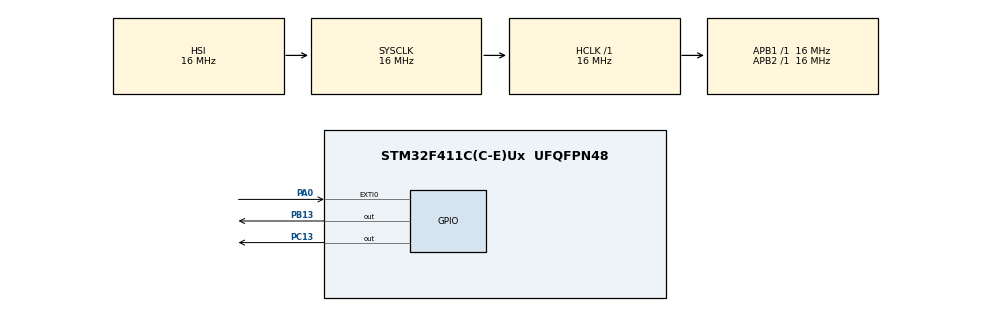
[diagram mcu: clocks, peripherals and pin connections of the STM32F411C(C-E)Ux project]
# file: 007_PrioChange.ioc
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Mcu.Family=STM32F4
Mcu.Name=STM32F411C(C-E)Ux
Mcu.Package=UFQFPN48
NVIC.EXTI0_IRQn=true\:6\:0\:true\:false\:true\:true\:true\:true
NVIC.PriorityGroup=NVIC_PRIORITYGROUP_4
NVIC.TIM2_IRQn=true\:15\:0\:false\:false\:true\:false\:true\:true
NVIC.TimeBase=TIM2_IRQn
NVIC.TimeBaseIP=TIM2
PA0-WKUP.GPIO_ModeDefaultEXTI=GPIO_MODE_IT_FALLING
PA0-WKUP.GPIO_PuPd=GPIO_PULLUP
PA0-WKUP.Signal=GPXTI0
PB13.Signal=GPIO_Output
PC13-ANTI_TAMP.Signal=GPIO_Output
ProjectManager.HeapSize=0x200
ProjectManager.StackSize=0x400
ProjectManager.TargetToolchain=STM32CubeIDE
RCC.AHBFreq_Value=16000000
RCC.APB1Freq_Value=16000000
RCC.APB2Freq_Value=16000000
RCC.CortexFreq_Value=16000000
RCC.HSE_VALUE=25000000
RCC.HSI_VALUE=16000000
RCC.LSE_VALUE=32768
RCC.SYSCLKFreq_VALUE=16000000
RCC.VCOOutputFreq_Value=192000000
VP_SYS_VS_tim2.Mode=TIM2
board=custom

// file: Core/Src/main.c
/* USER CODE BEGIN Header */
/**
  ******************************************************************************
  * @file           : main.c
  * @brief          : Main program body
  ******************************************************************************
  * @attention
  *
  * Copyright (c) 2025 STMicroelectronics.
  * All rights reserved.
  *
  * This software is licensed under terms that can be found in the LICENSE file
  * in the root directory of this software component.
  * If no LICENSE file comes with this software, it is provided AS-IS.
  *
  ******************************************************************************
  */
/* USER CODE END Header */
#include "main.h"

/* USER CODE BEGIN Includes */
#include <stdio.h>
#include "FreeRTOS.h"
#include "task.h"

/* USER CODE END Includes */

/* USER CODE BEGIN PV */
#define DWT_CTRL   ( *(volatile uint32_t*) 0xE0001000 )
/* USER CODE END PV */

void SystemClock_Config(void);
static void MX_GPIO_Init(void);
/* USER CODE BEGIN PFP */
static void led1_handler(void* parameters);
static void led2_handler(void* parameters);
TaskHandle_t task1_handler, task2_handler;
BaseType_t btn_status = 0;
/* USER CODE END PFP */

int main(void)
{

  /* USER CODE BEGIN 1 */
	BaseType_t status;
  /* USER CODE END 1 */

  /* MCU Configuration--------------------------------------------------------*/

  /* Reset of all peripherals, Initializes the Flash interface and the Systick. */
  HAL_Init();

  /* Configure the system clock */
  SystemClock_Config();

  /* Initialize all configured peripherals */
  MX_GPIO_Init();
  /* USER CODE BEGIN 2 */
  //enable the cycle count //
  DWT_CTRL |= (1 << 0);

  SEGGER_SYSVIEW_Conf();
  SEGGER_SYSVIEW_Start();

  status = xTaskCreate(led1_handler, "Task - 1", configMINIMAL_STACK_SIZE * 2, "Executing task - 1", 3, &task1_handler);
  configASSERT(status == pdPASS);

  status = xTaskCreate(led2_handler, "Task - 2", configMINIMAL_STACK_SIZE * 2, "Executing task - 2", 2, &task2_handler);
  configASSERT(status == pdPASS);

  vTaskStartScheduler();

  /* USER CODE END 2 */

  /* Infinite loop */
  while (1)
  {

  }
}

void SystemClock_Config(void)
{
  RCC_OscInitTypeDef RCC_OscInitStruct = {0};
  RCC_ClkInitTypeDef RCC_ClkInitStruct = {0};

  /** Configure the main internal regulator output voltage
  */
  __HAL_RCC_PWR_CLK_ENABLE();
  __HAL_PWR_VOLTAGESCALING_CONFIG(PWR_REGULATOR_VOLTAGE_SCALE1);

  /** Initializes the RCC Oscillators according to the specified parameters
  * in the RCC_OscInitTypeDef structure.
  */
  RCC_OscInitStruct.OscillatorType = RCC_OSCILLATORTYPE_HSI;
  RCC_OscInitStruct.HSIState = RCC_HSI_ON;
  RCC_OscInitStruct.HSICalibrationValue = RCC_HSICALIBRATION_DEFAULT;
  RCC_OscInitStruct.PLL.PLLState = RCC_PLL_NONE;
  if (HAL_RCC_OscConfig(&RCC_OscInitStruct) != HAL_OK)
  {
    Error_Handler();
  }

  /** Initializes the CPU, AHB and APB buses clocks
  */
  RCC_ClkInitStruct.ClockType = RCC_CLOCKTYPE_HCLK|RCC_CLOCKTYPE_SYSCLK
                              |RCC_CLOCKTYPE_PCLK1|RCC_CLOCKTYPE_PCLK2;
  RCC_ClkInitStruct.SYSCLKSource = RCC_SYSCLKSOURCE_HSI;
  RCC_ClkInitStruct.AHBCLKDivider = RCC_SYSCLK_DIV1;
  RCC_ClkInitStruct.APB1CLKDivider = RCC_HCLK_DIV1;
  RCC_ClkInitStruct.APB2CLKDivider = RCC_HCLK_DIV1;

  if (HAL_RCC_ClockConfig(&RCC_ClkInitStruct, FLASH_LATENCY_0) != HAL_OK)
  {
    Error_Handler();
  }
}

static void MX_GPIO_Init(void)
{
  GPIO_InitTypeDef GPIO_InitStruct = {0};

  /* GPIO Ports Clock Enable */
  __HAL_RCC_GPIOC_CLK_ENABLE();
  __HAL_RCC_GPIOA_CLK_ENABLE();
  __HAL_RCC_GPIOB_CLK_ENABLE();

  /*Configure GPIO pin Output Level */
  HAL_GPIO_WritePin(GPIOC, GPIO_PIN_13, GPIO_PIN_RESET);

  /*Configure GPIO pin Output Level */
  HAL_GPIO_WritePin(GPIOB, GPIO_PIN_13, GPIO_PIN_RESET);

  /*Configure GPIO pin : PC13 */
  GPIO_InitStruct.Pin = GPIO_PIN_13;
  GPIO_InitStruct.Mode = GPIO_MODE_OUTPUT_PP;
  GPIO_InitStruct.Pull = GPIO_NOPULL;
  GPIO_InitStruct.Speed = GPIO_SPEED_FREQ_LOW;
  HAL_GPIO_Init(GPIOC, &GPIO_InitStruct);

  /*Configure GPIO pin : PA0 */
  GPIO_InitStruct.Pin = GPIO_PIN_0;
  GPIO_InitStruct.Mode = GPIO_MODE_IT_FALLING;
  GPIO_InitStruct.Pull = GPIO_PULLUP;
  HAL_GPIO_Init(GPIOA, &GPIO_InitStruct);

  /*Configure GPIO pin : PB13 */
  GPIO_InitStruct.Pin = GPIO_PIN_13;
  GPIO_InitStruct.Mode = GPIO_MODE_OUTPUT_PP;
  GPIO_InitStruct.Pull = GPIO_NOPULL;
  GPIO_InitStruct.Speed = GPIO_SPEED_FREQ_LOW;
  HAL_GPIO_Init(GPIOB, &GPIO_InitStruct);

  /* EXTI interrupt init*/
  HAL_NVIC_SetPriority(EXTI0_IRQn, 6, 0);
  HAL_NVIC_EnableIRQ(EXTI0_IRQn);

}

/* USER CODE BEGIN 4 */
void switch_priority(void)
{
	UBaseType_t prio1, prio2;
	TaskHandle_t curr;
	BaseType_t switch_prio = 0;

	portENTER_CRITICAL();
	if(btn_status)
	{
		btn_status = 0;
		switch_prio = 1;
	}
	portEXIT_CRITICAL();

	if(switch_prio)
	{
//		t1 = xTaskGetHandle("Task - 1");
//		t2 = xTaskGetHandle("Task - 2");
		prio1 = uxTaskPriorityGet(task1_handler);
		prio2 = uxTaskPriorityGet(task2_handler);

		curr = xTaskGetCurrentTaskHandle();

		if(curr == task1_handler)
		{
			vTaskPrioritySet(task1_handler, prio2);
			vTaskPrioritySet(task2_handler, prio1);
		}
		else
		{
			vTaskPrioritySet(task2_handler, prio1);
			vTaskPrioritySet(task1_handler, prio2);
		}

	}

}
void button_interrupt_handler(void)
{
	traceISR_ENTER();
	btn_status = 1;
	traceISR_EXIT();
}
static void led1_handler(void* parameters)
{
	while(1)
	{	HAL_GPIO_TogglePin(GPIOC, GPIO_PIN_13);
//		vTaskDelay(pdMS_TO_TICKS(1000));
		HAL_Delay(150);
		switch_priority();
	}
}

static void led2_handler(void* parameters)
{
	while(1)
	{
		HAL_GPIO_TogglePin(GPIOB, GPIO_PIN_13);
//		vTaskDelay(pdMS_TO_TICKS(100));
		HAL_Delay(100);
		switch_priority();
	}
}

/* USER CODE END 4 */

void HAL_TIM_PeriodElapsedCallback(TIM_HandleTypeDef *htim)
{
  if (htim->Instance == TIM2)
  {
    HAL_IncTick();
  }
}

void Error_Handler(void)
{
  __disable_irq();
  while (1)
  {
  }
}
